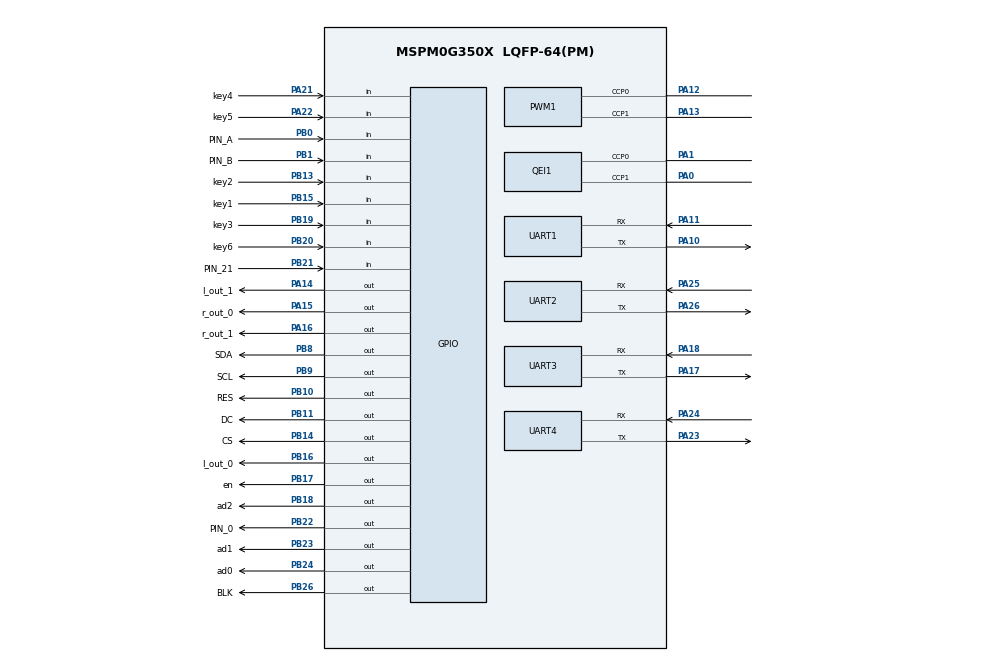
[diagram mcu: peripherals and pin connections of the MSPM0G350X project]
/**
 * @cliArgs --device "MSPM0G350X" --part "Default" --package "LQFP-64(PM)" --product "mspm0_sdk@2.05.00.05"
 * @versions {"tool":"1.24.1+4189"}
 */

/**
 * Import the modules used in this configuration.
 */
const ADC12   = scripting.addModule("/ti/driverlib/ADC12", {}, false);
const ADC121  = ADC12.addInstance();
const GPIO    = scripting.addModule("/ti/driverlib/GPIO", {}, false);
const GPIO1   = GPIO.addInstance();
const GPIO2   = GPIO.addInstance();
const GPIO3   = GPIO.addInstance();
const GPIO4   = GPIO.addInstance();
const GPIO5   = GPIO.addInstance();
const GPIO6   = GPIO.addInstance();
const PWM     = scripting.addModule("/ti/driverlib/PWM", {}, false);
const PWM1    = PWM.addInstance();
const QEI     = scripting.addModule("/ti/driverlib/QEI", {}, false);
const QEI1    = QEI.addInstance();
const SYSCTL  = scripting.addModule("/ti/driverlib/SYSCTL");
const SYSTICK = scripting.addModule("/ti/driverlib/SYSTICK");
const TIMER   = scripting.addModule("/ti/driverlib/TIMER", {}, false);
const TIMER1  = TIMER.addInstance();
const UART    = scripting.addModule("/ti/driverlib/UART", {}, false);
const UART1   = UART.addInstance();
const UART2   = UART.addInstance();
const UART3   = UART.addInstance();
const UART4   = UART.addInstance();

/**
 * Write custom configuration values to the imported modules.
 */
const divider9       = system.clockTree["UDIV"];
divider9.divideValue = 2;

const gate7  = system.clockTree["MFCLKGATE"];
gate7.enable = true;

const mux4       = system.clockTree["EXHFMUX"];
mux4.inputSelect = "EXHFMUX_XTAL";

const mux8       = system.clockTree["HSCLKMUX"];
mux8.inputSelect = "HSCLKMUX_SYSPLL2X";

const mux12       = system.clockTree["SYSPLLMUX"];
mux12.inputSelect = "zSYSPLLMUX_HFCLK";

const pinFunction4       = system.clockTree["HFXT"];
pinFunction4.inputFreq   = 40;
pinFunction4.enable      = true;
pinFunction4.HFXTStartup = 255;

ADC121.$name                      = "ADC12_0";
ADC121.enableDMA                  = false;
ADC121.sampClkSrc                 = "DL_ADC12_CLOCK_ULPCLK";
ADC121.sampleTime0                = "62.5ns";
ADC121.repeatMode                 = true;
ADC121.powerDownMode              = "DL_ADC12_POWER_DOWN_MODE_MANUAL";
ADC121.peripheral.$assign         = "ADC0";
ADC121.peripheral.adcPin0.$assign = "PA27";
ADC121.adcPin0Config.$name        = "ti_driverlib_gpio_GPIOPinGeneric10";

const Board = scripting.addModule("/ti/driverlib/Board", {}, false);

GPIO1.$name                              = "KEY";
GPIO1.associatedPins.create(7);
GPIO1.associatedPins[0].$name            = "PIN_21";
GPIO1.associatedPins[0].direction        = "INPUT";
GPIO1.associatedPins[0].assignedPort     = "PORTB";
GPIO1.associatedPins[0].assignedPin      = "21";
GPIO1.associatedPins[0].internalResistor = "PULL_UP";
GPIO1.associatedPins[0].pin.$assign      = "PB21";
GPIO1.associatedPins[1].$name            = "key1";
GPIO1.associatedPins[1].direction        = "INPUT";
GPIO1.associatedPins[1].internalResistor = "PULL_UP";
GPIO1.associatedPins[1].pin.$assign      = "PB15";
GPIO1.associatedPins[2].$name            = "key2";
GPIO1.associatedPins[2].direction        = "INPUT";
GPIO1.associatedPins[2].internalResistor = "PULL_UP";
GPIO1.associatedPins[2].pin.$assign      = "PB13";
GPIO1.associatedPins[3].$name            = "key3";
GPIO1.associatedPins[3].direction        = "INPUT";
GPIO1.associatedPins[3].pin.$assign      = "PB19";
GPIO1.associatedPins[4].$name            = "key4";
GPIO1.associatedPins[4].direction        = "INPUT";
GPIO1.associatedPins[4].pin.$assign      = "PA21";
GPIO1.associatedPins[5].$name            = "key5";
GPIO1.associatedPins[5].direction        = "INPUT";
GPIO1.associatedPins[5].pin.$assign      = "PA22";
GPIO1.associatedPins[6].$name            = "key6";
GPIO1.associatedPins[6].direction        = "INPUT";
GPIO1.associatedPins[6].pin.$assign      = "PB20";

GPIO2.$name                         = "LCD";
GPIO2.port                          = "PORTB";
GPIO2.associatedPins.create(6);
GPIO2.associatedPins[0].$name       = "SCL";
GPIO2.associatedPins[0].assignedPin = "9";
GPIO2.associatedPins[0].pin.$assign = "PB9";
GPIO2.associatedPins[1].$name       = "SDA";
GPIO2.associatedPins[1].assignedPin = "8";
GPIO2.associatedPins[1].pin.$assign = "PB8";
GPIO2.associatedPins[2].$name       = "RES";
GPIO2.associatedPins[2].assignedPin = "10";
GPIO2.associatedPins[2].pin.$assign = "PB10";
GPIO2.associatedPins[3].$name       = "DC";
GPIO2.associatedPins[3].assignedPin = "11";
GPIO2.associatedPins[3].pin.$assign = "PB11";
GPIO2.associatedPins[4].$name       = "CS";
GPIO2.associatedPins[4].assignedPin = "14";
GPIO2.associatedPins[4].pin.$assign = "PB14";
GPIO2.associatedPins[5].$name       = "BLK";
GPIO2.associatedPins[5].assignedPin = "26";
GPIO2.associatedPins[5].pin.$assign = "PB26";

GPIO3.$name                          = "GPIO_GRP_0";
GPIO3.associatedPins[0].$name        = "PIN_0";
GPIO3.associatedPins[0].assignedPort = "PORTB";
GPIO3.associatedPins[0].assignedPin  = "22";
GPIO3.associatedPins[0].pin.$assign  = "PB22";

GPIO4.$name                               = "soft_encoder";
GPIO4.associatedPins.create(2);
GPIO4.associatedPins[0].direction         = "INPUT";
GPIO4.associatedPins[0].assignedPort      = "PORTB";
GPIO4.associatedPins[0].assignedPin       = "0";
GPIO4.associatedPins[0].$name             = "PIN_A";
GPIO4.associatedPins[0].interruptEn       = true;
GPIO4.associatedPins[0].interruptPriority = "0";
GPIO4.associatedPins[0].polarity          = "RISE";
GPIO4.associatedPins[0].pin.$assign       = "PB0";
GPIO4.associatedPins[1].$name             = "PIN_B";
GPIO4.associatedPins[1].direction         = "INPUT";
GPIO4.associatedPins[1].assignedPort      = "PORTB";
GPIO4.associatedPins[1].assignedPin       = "1";
GPIO4.associatedPins[1].interruptEn       = true;
GPIO4.associatedPins[1].interruptPriority = "0";
GPIO4.associatedPins[1].polarity          = "RISE";
GPIO4.associatedPins[1].pin.$assign       = "PB1";

GPIO5.$name                         = "car";
GPIO5.associatedPins.create(4);
GPIO5.associatedPins[0].$name       = "l_out_0";
GPIO5.associatedPins[0].pin.$assign = "PB16";
GPIO5.associatedPins[1].$name       = "l_out_1";
GPIO5.associatedPins[1].pin.$assign = "PA14";
GPIO5.associatedPins[2].$name       = "r_out_0";
GPIO5.associatedPins[2].pin.$assign = "PA15";
GPIO5.associatedPins[3].$name       = "r_out_1";
GPIO5.associatedPins[3].pin.$assign = "PA16";

GPIO6.$name                         = "scale";
GPIO6.associatedPins.create(4);
GPIO6.associatedPins[0].$name       = "en";
GPIO6.associatedPins[0].pin.$assign = "PB17";
GPIO6.associatedPins[1].$name       = "ad2";
GPIO6.associatedPins[1].pin.$assign = "PB18";
GPIO6.associatedPins[2].$name       = "ad1";
GPIO6.associatedPins[2].pin.$assign = "PB23";
GPIO6.associatedPins[3].$name       = "ad0";
GPIO6.associatedPins[3].pin.$assign = "PB24";

PWM1.$name                              = "PWM_l";
PWM1.clockDivider                       = 2;
PWM1.timerCount                         = 2000;
PWM1.peripheral.$assign                 = "TIMG0";
PWM1.peripheral.ccp0Pin.$assign         = "PA12";
PWM1.peripheral.ccp1Pin.$assign         = "PA13";
PWM1.PWM_CHANNEL_0.$name                = "ti_driverlib_pwm_PWMTimerCC0";
PWM1.PWM_CHANNEL_0.invert               = true;
PWM1.PWM_CHANNEL_1.$name                = "ti_driverlib_pwm_PWMTimerCC1";
PWM1.PWM_CHANNEL_1.invert               = true;
PWM1.ccp0PinConfig.direction            = scripting.forceWrite("OUTPUT");
PWM1.ccp0PinConfig.hideOutputInversion  = scripting.forceWrite(false);
PWM1.ccp0PinConfig.onlyInternalResistor = scripting.forceWrite(false);
PWM1.ccp0PinConfig.passedPeripheralType = scripting.forceWrite("Digital");
PWM1.ccp0PinConfig.$name                = "ti_driverlib_gpio_GPIOPinGeneric3";
PWM1.ccp1PinConfig.direction            = scripting.forceWrite("OUTPUT");
PWM1.ccp1PinConfig.hideOutputInversion  = scripting.forceWrite(false);
PWM1.ccp1PinConfig.onlyInternalResistor = scripting.forceWrite(false);
PWM1.ccp1PinConfig.passedPeripheralType = scripting.forceWrite("Digital");
PWM1.ccp1PinConfig.$name                = "ti_driverlib_gpio_GPIOPinGeneric5";

QEI1.$name                          = "QEI_0";
QEI1.timerStartTimer                = true;
QEI1.peripheral.$assign             = "TIMG8";
QEI1.peripheral.ccp0Pin.$assign     = "PA1";
QEI1.peripheral.ccp1Pin.$assign     = "PA0";
QEI1.ccp0PinConfig.$name            = "ti_driverlib_gpio_GPIOPinGeneric2";
QEI1.ccp0PinConfig.enableConfig     = true;
QEI1.ccp0PinConfig.internalResistor = "PULL_DOWN";
QEI1.ccp1PinConfig.$name            = "ti_driverlib_gpio_GPIOPinGeneric4";
QEI1.ccp1PinConfig.enableConfig     = true;
QEI1.ccp1PinConfig.internalResistor = "PULL_DOWN";

SYSCTL.forceDefaultClkConfig = true;
SYSCTL.clockTreeEn           = true;
scripting.suppress("For best practices when the CPUCLK is running at 32MHz and above, clear the flash status bit using DL_FlashCTL_executeClearStatus\\(\\) before executing any flash operation\\. Otherwise there may be false positives\\.", SYSCTL);

SYSTICK.periodEnable    = true;
SYSTICK.interruptEnable = true;
SYSTICK.systickEnable   = true;
SYSTICK.period          = 80000;

TIMER1.$name            = "encoder";
TIMER1.timerClkDiv      = 8;
TIMER1.timerClkPrescale = 10;
TIMER1.timerPeriod      = "20 ms";
TIMER1.timerMode        = "PERIODIC";
TIMER1.interrupts       = ["ZERO"];

UART1.$name                    = "UART_0";
UART1.enableFIFO               = true;
UART1.rxFifoThreshold          = "DL_UART_RX_FIFO_LEVEL_ONE_ENTRY";
UART1.enableDMARX              = false;
UART1.enableDMATX              = false;
UART1.enabledInterrupts        = ["RX"];
UART1.peripheral.rxPin.$assign = "PA11";
UART1.peripheral.txPin.$assign = "PA10";
UART1.txPinConfig.$name        = "ti_driverlib_gpio_GPIOPinGeneric0";
UART1.rxPinConfig.$name        = "ti_driverlib_gpio_GPIOPinGeneric1";

UART2.$name                    = "UART_1";
UART2.enabledInterrupts        = ["RX"];
UART2.peripheral.rxPin.$assign = "PA25";
UART2.peripheral.txPin.$assign = "PA26";
UART2.txPinConfig.$name        = "ti_driverlib_gpio_GPIOPinGeneric8";
UART2.rxPinConfig.$name        = "ti_driverlib_gpio_GPIOPinGeneric9";

UART3.$name                    = "UART_2";
UART3.targetBaudRate           = 115200;
UART3.enabledInterrupts        = ["RX"];
UART3.peripheral.rxPin.$assign = "PA18";
UART3.peripheral.txPin.$assign = "PA17";
UART3.txPinConfig.$name        = "ti_driverlib_gpio_GPIOPinGeneric6";
UART3.rxPinConfig.$name        = "ti_driverlib_gpio_GPIOPinGeneric7";

UART4.$name                    = "UART_3";
UART4.enabledInterrupts        = ["RX"];
UART4.peripheral.rxPin.$assign = "PA24";
UART4.peripheral.txPin.$assign = "PA23";
UART4.txPinConfig.$name        = "ti_driverlib_gpio_GPIOPinGeneric11";
UART4.rxPinConfig.$name        = "ti_driverlib_gpio_GPIOPinGeneric12";

/**
 * Pinmux solution for unlocked pins/peripherals. This ensures that minor changes to the automatic solver in a future
 * version of the tool will not impact the pinmux you originally saw.  These lines can be completely deleted in order to
 * re-solve from scratch.
 */
pinFunction4.peripheral.$suggestSolution           = "SYSCTL";
pinFunction4.peripheral.hfxInPin.$suggestSolution  = "PA5";
pinFunction4.peripheral.hfxOutPin.$suggestSolution = "PA6";
Board.peripheral.$suggestSolution                  = "DEBUGSS";
Board.peripheral.swclkPin.$suggestSolution         = "PA20";
Board.peripheral.swdioPin.$suggestSolution         = "PA19";
TIMER1.peripheral.$suggestSolution                 = "TIMA0";
UART1.peripheral.$suggestSolution                  = "UART0";
UART2.peripheral.$suggestSolution                  = "UART3";
UART3.peripheral.$suggestSolution                  = "UART1";
UART4.peripheral.$suggestSolution                  = "UART2";
